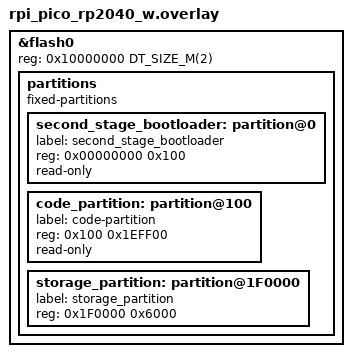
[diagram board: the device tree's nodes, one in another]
&flash0 {
	reg = <0x10000000 DT_SIZE_M(2)>;

	partitions {
		compatible = "fixed-partitions";
		#address-cells = <1>;
		#size-cells = <1>;

		/* Reserved memory for the second stage bootloader */
		second_stage_bootloader: partition@0 {
			label = "second_stage_bootloader";
			reg = <0x00000000 0x100>;
			read-only;
		};

		/*
		 * Usable flash. Starts at 0x100, after the bootloader. The partition
		 * size is 2MB minus the 0x100 bytes taken by the bootloader.
		 */
		code_partition: partition@100 {
			label = "code-partition";
			reg = <0x100 0x1EFF00>;
			read-only;
		};
	
		storage_partition: partition@1F0000 {
			label = "storage_partition";
			reg = < 0x1F0000 0x6000 >;
		};
        };
};
